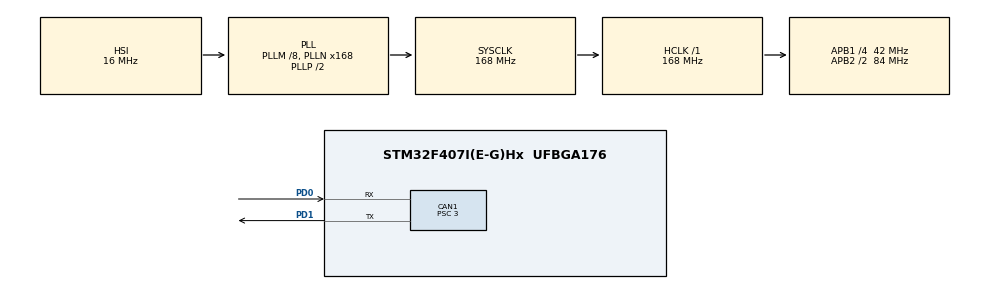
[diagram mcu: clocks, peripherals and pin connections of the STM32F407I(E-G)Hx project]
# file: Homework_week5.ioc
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CAN1.BS1=CAN_BS1_10TQ
CAN1.BS2=CAN_BS2_3TQ
CAN1.CalculateBaudRate=1000000
CAN1.CalculateTimeBit=1000
CAN1.CalculateTimeQuantum=71.42857142857143
CAN1.Prescaler=3
Mcu.Family=STM32F4
Mcu.Name=STM32F407I(E-G)Hx
Mcu.Package=UFBGA176
NVIC.CAN1_RX0_IRQn=true\:0\:0\:false\:false\:true\:true\:true\:true
NVIC.CAN1_RX1_IRQn=true\:0\:0\:false\:false\:true\:true\:true\:true
NVIC.CAN1_SCE_IRQn=true\:0\:0\:false\:false\:true\:true\:true\:true
NVIC.CAN1_TX_IRQn=true\:0\:0\:false\:false\:true\:true\:true\:true
NVIC.PriorityGroup=NVIC_PRIORITYGROUP_4
PA13.Mode=Serial_Wire
PA13.Signal=SYS_JTMS-SWDIO
PA14.Mode=Serial_Wire
PA14.Signal=SYS_JTCK-SWCLK
PD0.Mode=CAN_Activate
PD0.Signal=CAN1_RX
PD1.Mode=CAN_Activate
PD1.Signal=CAN1_TX
PH0-OSC_IN.Mode=HSE-External-Oscillator
PH0-OSC_IN.Signal=RCC_OSC_IN
PH1-OSC_OUT.Mode=HSE-External-Oscillator
PH1-OSC_OUT.Signal=RCC_OSC_OUT
ProjectManager.HeapSize=0x200
ProjectManager.StackSize=0x400
ProjectManager.TargetToolchain=Makefile
RCC.48MHZClocksFreq_Value=84000000
RCC.AHBFreq_Value=168000000
RCC.APB1CLKDivider=RCC_HCLK_DIV4
RCC.APB1Freq_Value=42000000
RCC.APB1TimFreq_Value=84000000
RCC.APB2CLKDivider=RCC_HCLK_DIV2
RCC.APB2Freq_Value=84000000
RCC.APB2TimFreq_Value=168000000
RCC.CortexFreq_Value=168000000
RCC.HCLKFreq_Value=168000000
RCC.HSE_VALUE=12000000
RCC.HSI_VALUE=16000000
RCC.LSE_VALUE=32768
RCC.PLLM=8
RCC.PLLN=168
RCC.SYSCLKFreq_VALUE=168000000
RCC.SYSCLKSource=RCC_SYSCLKSOURCE_PLLCLK
RCC.VCOOutputFreq_Value=336000000
board=custom

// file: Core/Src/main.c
/* USER CODE BEGIN Header */
/**
  ******************************************************************************
  * @file           : main.c
  * @brief          : Main program body
  ******************************************************************************
  * @attention
  *
  * Copyright (c) 2026 STMicroelectronics.
  * All rights reserved.
  *
  * This software is licensed under terms that can be found in the LICENSE file
  * in the root directory of this software component.
  * If no LICENSE file comes with this software, it is provided AS-IS.
  *
  ******************************************************************************
  */
/* USER CODE END Header */
#include "main.h"
#include "can.h"
#include "gpio.h"

/* USER CODE BEGIN Includes */
#include "WEI_can.h"
#include <math.h>
/* USER CODE END Includes */

void SystemClock_Config(void);

/* USER CODE BEGIN 0 */
DJI_Motor_Controller Line1;
CANInstance motor2;
DJI_Motor_Measure_s motor2_measure;

CAN_FilterTypeDef can_filter_conf;
uint8_t RTR = 0;
uint8_t IDE = 0;
uint8_t EXID = 0;

float t = 0;//计时变量
int16_t speed = 0;

uint8_t Data[8] = {0};

uint8_t can_rx_buff[8];
CAN_RxHeaderTypeDef rxconf; //接收头段

CAN_TxHeaderTypeDef Tempconf;

uint8_t test = 0;
/* USER CODE END 0 */

int main(void)
{

  /* MCU Configuration--------------------------------------------------------*/

  /* Reset of all peripherals, Initializes the Flash interface and the Systick. */
  HAL_Init();

  /* Configure the system clock */
  SystemClock_Config();

  /* Initialize all configured peripherals */
  MX_GPIO_Init();
  MX_CAN1_Init();
  /* USER CODE BEGIN 2 */

  motor2.rx_id = 0x202;
  WEI_CAN_DJIContorller_Init(&Line1);
  WEI_CAN_MotorInstance_Init(&motor2_measure,&motor2,&Line1,2);

  //配置Line1的发送部分

  Line1.tx_id = 0x200;
  Line1.hcanHandle = &hcan1;
  Tempconf.RTR = 0;
  Tempconf.DLC = 8;
  Tempconf.IDE = 0;
  Tempconf.StdId = Line1.tx_id;

  Line1.txconf = &Tempconf;

  HAL_CAN_Start(&hcan1);
  //配置过滤器
  can_filter_conf.FilterMode = CAN_FILTERMODE_IDLIST;
  can_filter_conf.FilterScale = CAN_FILTERSCALE_16BIT;
  can_filter_conf.FilterFIFOAssignment = CAN_RX_FIFO0;
  can_filter_conf.SlaveStartFilterBank = 14;
  can_filter_conf.FilterIdLow = (0x202 << 5) | (RTR << 4) | (IDE << 3) | EXID;
  can_filter_conf.FilterBank = 1;
  can_filter_conf.FilterActivation = CAN_FILTER_ENABLE;

  HAL_CAN_ConfigFilter(&hcan1,&can_filter_conf);
  __HAL_CAN_ENABLE_IT(&hcan1,CAN_IT_RX_FIFO0_MSG_PENDING);

  /* USER CODE END 2 */

  /* Infinite loop */
  while (1)
  {

    /* USER CODE BEGIN 3 */
    speed = 1000 * sin(t);

    if(HAL_CAN_GetTxMailboxesFreeLevel(&hcan1) == 0);
    else
    {
      Data[0] = 0;
      Data[1] = 0;
      Data[2] = (uint8_t)(speed >> 8);
      Data[3] = (uint8_t)(speed & 0xFF);
      Data[4] = 0;
      Data[5] = 0;
      Data[6] = 0;
      Data[7] = 0;

      HAL_CAN_AddTxMessage(&hcan1,Line1.txconf,Data,&Line1.tx_mailbox);
    }
    t += 0.2f;

    HAL_Delay(10);

  }
  /* USER CODE END 3 */
}

void SystemClock_Config(void)
{
  RCC_OscInitTypeDef RCC_OscInitStruct = {0};
  RCC_ClkInitTypeDef RCC_ClkInitStruct = {0};

  /** Configure the main internal regulator output voltage
  */
  __HAL_RCC_PWR_CLK_ENABLE();
  __HAL_PWR_VOLTAGESCALING_CONFIG(PWR_REGULATOR_VOLTAGE_SCALE1);

  /** Initializes the RCC Oscillators according to the specified parameters
  * in the RCC_OscInitTypeDef structure.
  */
  RCC_OscInitStruct.OscillatorType = RCC_OSCILLATORTYPE_HSI;
  RCC_OscInitStruct.HSIState = RCC_HSI_ON;
  RCC_OscInitStruct.HSICalibrationValue = RCC_HSICALIBRATION_DEFAULT;
  RCC_OscInitStruct.PLL.PLLState = RCC_PLL_ON;
  RCC_OscInitStruct.PLL.PLLSource = RCC_PLLSOURCE_HSI;
  RCC_OscInitStruct.PLL.PLLM = 8;
  RCC_OscInitStruct.PLL.PLLN = 168;
  RCC_OscInitStruct.PLL.PLLP = RCC_PLLP_DIV2;
  RCC_OscInitStruct.PLL.PLLQ = 4;
  if (HAL_RCC_OscConfig(&RCC_OscInitStruct) != HAL_OK)
  {
    Error_Handler();
  }

  /** Initializes the CPU, AHB and APB buses clocks
  */
  RCC_ClkInitStruct.ClockType = RCC_CLOCKTYPE_HCLK|RCC_CLOCKTYPE_SYSCLK
                              |RCC_CLOCKTYPE_PCLK1|RCC_CLOCKTYPE_PCLK2;
  RCC_ClkInitStruct.SYSCLKSource = RCC_SYSCLKSOURCE_PLLCLK;
  RCC_ClkInitStruct.AHBCLKDivider = RCC_SYSCLK_DIV1;
  RCC_ClkInitStruct.APB1CLKDivider = RCC_HCLK_DIV4;
  RCC_ClkInitStruct.APB2CLKDivider = RCC_HCLK_DIV2;

  if (HAL_RCC_ClockConfig(&RCC_ClkInitStruct, FLASH_LATENCY_5) != HAL_OK)
  {
    Error_Handler();
  }
}

/* USER CODE BEGIN 4 */
void HAL_CAN_RxFifo0MsgPendingCallback(CAN_HandleTypeDef* hcan)
{
  test += 1;
  WEI_CAN_RxExchange(hcan,CAN_RX_FIFO0,&Line1);
}

void HAL_CAN_RxFifo1MsgPendingCallback(CAN_HandleTypeDef* hcan)
{
  test += 1;
  WEI_CAN_RxExchange(hcan,CAN_RX_FIFO1,&Line1);
}
/* USER CODE END 4 */

void Error_Handler(void)
{
  __disable_irq();
  while (1)
  {
  }
}
